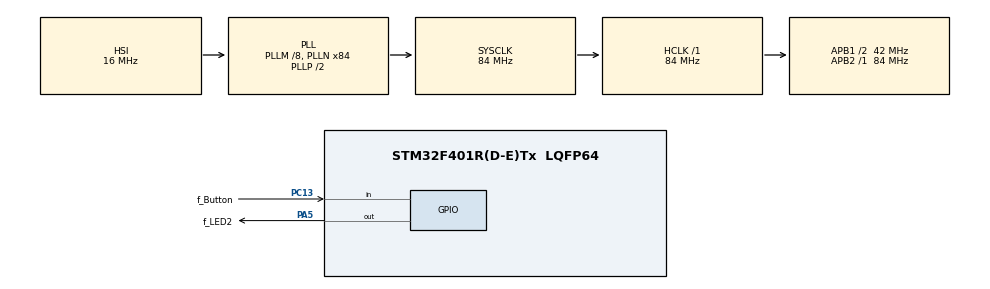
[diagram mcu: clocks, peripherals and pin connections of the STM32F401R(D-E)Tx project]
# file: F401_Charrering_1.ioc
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Mcu.Family=STM32F4
Mcu.Name=STM32F401R(D-E)Tx
Mcu.Package=LQFP64
NVIC.PriorityGroup=NVIC_PRIORITYGROUP_4
PA13.Mode=Serial_Wire
PA13.Signal=SYS_JTMS-SWDIO
PA14.Mode=Serial_Wire
PA14.Signal=SYS_JTCK-SWCLK
PA5.GPIO_Label=f_LED2
PA5.Signal=GPIO_Output
PC13-ANTI_TAMP.GPIO_Label=f_Button
PC13-ANTI_TAMP.GPIO_Mode=GPIO_MODE_INPUT
PC13-ANTI_TAMP.Signal=GPIO_Input
ProjectManager.HeapSize=0x200
ProjectManager.StackSize=0x400
ProjectManager.TargetToolchain=STM32CubeIDE
RCC.48MHZClocksFreq_Value=42000000
RCC.AHBFreq_Value=84000000
RCC.APB1CLKDivider=RCC_HCLK_DIV2
RCC.APB1Freq_Value=42000000
RCC.APB1TimFreq_Value=84000000
RCC.APB2Freq_Value=84000000
RCC.APB2TimFreq_Value=84000000
RCC.CortexFreq_Value=84000000
RCC.HCLKFreq_Value=84000000
RCC.HSE_VALUE=25000000
RCC.HSI_VALUE=16000000
RCC.LSE_VALUE=32768
RCC.PLLM=8
RCC.PLLN=84
RCC.SYSCLKFreq_VALUE=84000000
RCC.SYSCLKSource=RCC_SYSCLKSOURCE_PLLCLK
RCC.VCOOutputFreq_Value=168000000
board=custom

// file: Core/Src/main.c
/* USER CODE BEGIN Header */
/**
  ******************************************************************************
  * @file           : main.c
  * @brief          : Main program body
  ******************************************************************************
  * @attention
  *
  * <h2><center>&copy; Copyright (c) 2021 STMicroelectronics.
  * All rights reserved.</center></h2>
  *
  * This software component is licensed by ST under BSD 3-Clause license,
  * the "License"; You may not use this file except in compliance with the
  * License. You may obtain a copy of the License at:
  *                        opensource.org/licenses/BSD-3-Clause
  *
  ******************************************************************************
  */
/* USER CODE END Header */
#include "main.h"

void SystemClock_Config(void);
static void MX_GPIO_Init(void);

/* USER CODE BEGIN 0 */
#define MAX_CHATTERING_COUNT	5

/* USER CODE END 0 */

int main(void)
{
  /* USER CODE BEGIN 1 */
unsigned char f_Button_count = 0;
unsigned char f_new_Button = 0;
  /* USER CODE END 1 */

  /* MCU Configuration--------------------------------------------------------*/

  /* Reset of all peripherals, Initializes the Flash interface and the Systick. */
  HAL_Init();

  /* Configure the system clock */
  SystemClock_Config();

  /* Initialize all configured peripherals */
  MX_GPIO_Init();

  /* Infinite loop */
  while (1)
  {

    /* USER CODE BEGIN 3 */
//	  채러팅 방지 코딩
//	  60ms 마다 체크할 때 버튼 값이 0이 5번 인지하면 led에 불이 들어오기
//	  버튼을 누른 상태이면 채터링으로 인해 카운트가 5번이상이면
	  if((HAL_GPIO_ReadPin(GPIOC, f_Button_Pin)==0))
	  {
		  if(f_Button_count>MAX_CHATTERING_COUNT)
		  {
			  f_new_Button = 1;
		  }
		  else
		  {
			  HAL_Delay(60);
			  f_Button_count++;
			  f_new_Button = 0;
		  }
	  }

	  else if(HAL_GPIO_ReadPin(GPIOC, f_Button_Pin)==1)
	  {
		  f_Button_count = 0;
		  f_new_Button = 0;
	  }

	  if(f_new_Button==1)
	  {
		  HAL_GPIO_WritePin(f_LED2_GPIO_Port, f_LED2_Pin, GPIO_PIN_SET);
	  }

	  else
	  {
		  HAL_GPIO_WritePin(f_LED2_GPIO_Port, f_LED2_Pin, GPIO_PIN_RESET);
	  }
  }
  /* USER CODE END 3 */
}

void SystemClock_Config(void)
{
  RCC_OscInitTypeDef RCC_OscInitStruct = {0};
  RCC_ClkInitTypeDef RCC_ClkInitStruct = {0};

  /** Configure the main internal regulator output voltage
  */
  __HAL_RCC_PWR_CLK_ENABLE();
  __HAL_PWR_VOLTAGESCALING_CONFIG(PWR_REGULATOR_VOLTAGE_SCALE2);
  /** Initializes the RCC Oscillators according to the specified parameters
  * in the RCC_OscInitTypeDef structure.
  */
  RCC_OscInitStruct.OscillatorType = RCC_OSCILLATORTYPE_HSI;
  RCC_OscInitStruct.HSIState = RCC_HSI_ON;
  RCC_OscInitStruct.HSICalibrationValue = RCC_HSICALIBRATION_DEFAULT;
  RCC_OscInitStruct.PLL.PLLState = RCC_PLL_ON;
  RCC_OscInitStruct.PLL.PLLSource = RCC_PLLSOURCE_HSI;
  RCC_OscInitStruct.PLL.PLLM = 8;
  RCC_OscInitStruct.PLL.PLLN = 84;
  RCC_OscInitStruct.PLL.PLLP = RCC_PLLP_DIV2;
  RCC_OscInitStruct.PLL.PLLQ = 4;
  if (HAL_RCC_OscConfig(&RCC_OscInitStruct) != HAL_OK)
  {
    Error_Handler();
  }
  /** Initializes the CPU, AHB and APB buses clocks
  */
  RCC_ClkInitStruct.ClockType = RCC_CLOCKTYPE_HCLK|RCC_CLOCKTYPE_SYSCLK
                              |RCC_CLOCKTYPE_PCLK1|RCC_CLOCKTYPE_PCLK2;
  RCC_ClkInitStruct.SYSCLKSource = RCC_SYSCLKSOURCE_PLLCLK;
  RCC_ClkInitStruct.AHBCLKDivider = RCC_SYSCLK_DIV1;
  RCC_ClkInitStruct.APB1CLKDivider = RCC_HCLK_DIV2;
  RCC_ClkInitStruct.APB2CLKDivider = RCC_HCLK_DIV1;

  if (HAL_RCC_ClockConfig(&RCC_ClkInitStruct, FLASH_LATENCY_2) != HAL_OK)
  {
    Error_Handler();
  }
}

static void MX_GPIO_Init(void)
{
  GPIO_InitTypeDef GPIO_InitStruct = {0};

  /* GPIO Ports Clock Enable */
  __HAL_RCC_GPIOC_CLK_ENABLE();
  __HAL_RCC_GPIOA_CLK_ENABLE();

  /*Configure GPIO pin Output Level */
  HAL_GPIO_WritePin(f_LED2_GPIO_Port, f_LED2_Pin, GPIO_PIN_RESET);

  /*Configure GPIO pin : f_Button_Pin */
  GPIO_InitStruct.Pin = f_Button_Pin;
  GPIO_InitStruct.Mode = GPIO_MODE_INPUT;
  GPIO_InitStruct.Pull = GPIO_NOPULL;
  HAL_GPIO_Init(c, &GPIO_InitStruct);

  /*Configure GPIO pin : f_LED2_Pin */
  GPIO_InitStruct.Pin = f_LED2_Pin;
  GPIO_InitStruct.Mode = GPIO_MODE_OUTPUT_PP;
  GPIO_InitStruct.Pull = GPIO_NOPULL;
  GPIO_InitStruct.Speed = GPIO_SPEED_FREQ_LOW;
  HAL_GPIO_Init(f_LED2_GPIO_Port, &GPIO_InitStruct);

}

void Error_Handler(void)
{
  __disable_irq();
  while (1)
  {
  }
}

/************************ (C) COPYRIGHT STMicroelectronics *****END OF FILE****/
